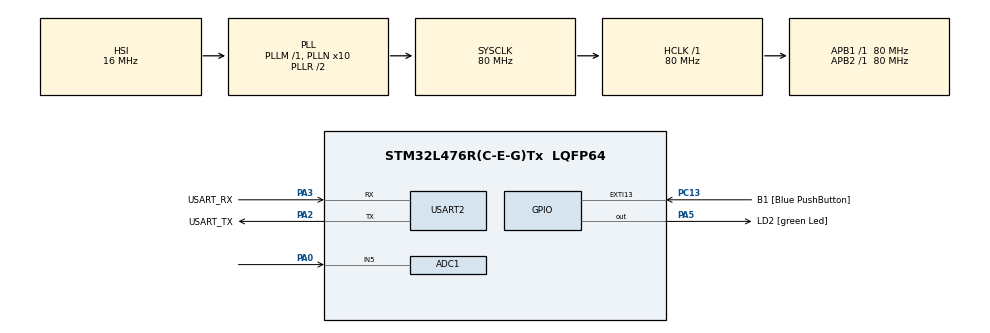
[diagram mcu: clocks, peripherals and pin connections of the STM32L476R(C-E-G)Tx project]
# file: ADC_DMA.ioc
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ADC1.Channel-1\#ChannelRegularConversion=ADC_CHANNEL_5
ADC1.ContinuousConvMode=ENABLE
ADC1.DMAContinuousRequests=ENABLE
ADC1.NbrOfConversionFlag=1
ADC1.OffsetNumber-1\#ChannelRegularConversion=ADC_OFFSET_NONE
ADC1.Rank-1\#ChannelRegularConversion=1
ADC1.SamplingTime-1\#ChannelRegularConversion=ADC_SAMPLETIME_2CYCLES_5
ADC1.master=1
Dma.ADC1.0.Direction=DMA_PERIPH_TO_MEMORY
Dma.ADC1.0.Instance=DMA1_Channel1
Dma.ADC1.0.MemDataAlignment=DMA_MDATAALIGN_HALFWORD
Dma.ADC1.0.MemInc=DMA_MINC_ENABLE
Dma.ADC1.0.Mode=DMA_CIRCULAR
Dma.ADC1.0.PeriphDataAlignment=DMA_PDATAALIGN_HALFWORD
Dma.ADC1.0.PeriphInc=DMA_PINC_DISABLE
Dma.ADC1.0.Priority=DMA_PRIORITY_LOW
Dma.Request0=ADC1
Mcu.Family=STM32L4
Mcu.Name=STM32L476R(C-E-G)Tx
Mcu.Package=LQFP64
NVIC.DMA1_Channel1_IRQn=true\:0\:0\:false\:false\:true\:false\:true\:true
NVIC.PriorityGroup=NVIC_PRIORITYGROUP_4
PA0.Signal=ADCx_IN5
PA13\ (JTMS-SWDIO).GPIO_Label=TMS
PA13\ (JTMS-SWDIO).Mode=Serial_Wire
PA13\ (JTMS-SWDIO).Signal=SYS_JTMS-SWDIO
PA14\ (JTCK-SWCLK).GPIO_Label=TCK
PA14\ (JTCK-SWCLK).Mode=Serial_Wire
PA14\ (JTCK-SWCLK).Signal=SYS_JTCK-SWCLK
PA2.GPIO_Label=USART_TX
PA2.GPIO_Mode=GPIO_MODE_AF_PP
PA2.GPIO_PuPd=GPIO_NOPULL
PA2.GPIO_Speed=GPIO_SPEED_FREQ_VERY_HIGH
PA2.Mode=Asynchronous
PA2.Signal=USART2_TX
PA3.GPIO_Label=USART_RX
PA3.GPIO_Mode=GPIO_MODE_AF_PP
PA3.GPIO_PuPd=GPIO_NOPULL
PA3.GPIO_Speed=GPIO_SPEED_FREQ_VERY_HIGH
PA3.Mode=Asynchronous
PA3.Signal=USART2_RX
PA5.GPIO_Label=LD2 [green Led]
PA5.GPIO_ModeDefaultOutputPP=GPIO_MODE_OUTPUT_PP
PA5.GPIO_PuPd=GPIO_NOPULL
PA5.GPIO_Speed=GPIO_SPEED_FREQ_LOW
PA5.Signal=GPIO_Output
PB3\ (JTDO-TRACESWO).GPIO_Label=SWO
PB3\ (JTDO-TRACESWO).Signal=SYS_JTDO-SWO
PC13.GPIO_Label=B1 [Blue PushButton]
PC13.GPIO_ModeDefaultEXTI=GPIO_MODE_IT_FALLING
PC13.GPIO_PuPd=GPIO_NOPULL
PC13.Signal=GPXTI13
PC14-OSC32_IN\ (PC14).Mode=LSE-External-Oscillator
PC14-OSC32_IN\ (PC14).Signal=RCC_OSC32_IN
PC15-OSC32_OUT\ (PC15).Mode=LSE-External-Oscillator
PC15-OSC32_OUT\ (PC15).Signal=RCC_OSC32_OUT
PH0-OSC_IN\ (PH0).Mode=HSE-External-Clock-Source
PH0-OSC_IN\ (PH0).Signal=RCC_OSC_IN
PH1-OSC_OUT\ (PH1).Signal=RCC_OSC_OUT
ProjectManager.HeapSize=0x200
ProjectManager.StackSize=0x400
ProjectManager.TargetToolchain=STM32CubeIDE
RCC.ADCFreq_Value=64000000
RCC.AHBFreq_Value=80000000
RCC.APB1Freq_Value=80000000
RCC.APB1TimFreq_Value=80000000
RCC.APB2Freq_Value=80000000
RCC.APB2TimFreq_Value=80000000
RCC.CortexFreq_Value=80000000
RCC.HCLKFreq_Value=80000000
RCC.HSE_VALUE=8000000
RCC.HSI_VALUE=16000000
RCC.MSI_VALUE=4000000
RCC.PLLN=10
RCC.PLLSourceVirtual=RCC_PLLSOURCE_HSI
RCC.SYSCLKFreq_VALUE=80000000
RCC.SYSCLKSource=RCC_SYSCLKSOURCE_PLLCLK
RCC.USBFreq_Value=64000000
RCC.VCOOutputFreq_Value=160000000
SH.ADCx_IN5.0=ADC1_IN5,IN5-Single-Ended
USART2.VirtualMode-Asynchronous=VM_ASYNC
board=NUCLEO-L476RG

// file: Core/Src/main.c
/* USER CODE BEGIN Header */
/**
  ******************************************************************************
  * @file           : main.c
  * @brief          : Main program body
  ******************************************************************************
  * @attention
  *
  * Copyright (c) 2025 STMicroelectronics.
  * All rights reserved.
  *
  * This software is licensed under terms that can be found in the LICENSE file
  * in the root directory of this software component.
  * If no LICENSE file comes with this software, it is provided AS-IS.
  *
  ******************************************************************************
  */
/* USER CODE END Header */
#include "main.h"
#include<stdio.h>
#include "string.h"

ADC_HandleTypeDef hadc1;
DMA_HandleTypeDef hdma_adc1;

UART_HandleTypeDef huart2;

void SystemClock_Config(void);
static void MX_GPIO_Init(void);
static void MX_DMA_Init(void);
static void MX_USART2_UART_Init(void);
static void MX_ADC1_Init(void);

/* USER CODE BEGIN 0 */
uint32_t adc_val = 0; // Variable to store ADC value

// Callback function called when ADC conversion is complete (DMA mode)
void HAL_ADC_ConvCpltCallback(ADC_HandleTypeDef* hadc)
{
  if (hadc->Instance == ADC1) // Check if callback is for ADC1
  {
    HAL_GPIO_TogglePin(LD2_GPIO_Port, LD2_Pin); // Toggle LED2 on each ADC update
  }
}
/* USER CODE END 0 */

int main(void)
{

  /* MCU Configuration--------------------------------------------------------*/

  HAL_Init(); // Initialize HAL library

  SystemClock_Config(); // Configure system clock

  MX_GPIO_Init();       // Initialize GPIO
  MX_DMA_Init();        // Initialize DMA
  MX_USART2_UART_Init();// Initialize UART2
  MX_ADC1_Init();       // Initialize ADC1

  /* USER CODE BEGIN 2 */
  HAL_ADC_Start_DMA(&hadc1, &adc_val, 1); // Start ADC1 in DMA mode to store result in adc_val
  /* USER CODE END 2 */

  char msg[50]; // Buffer to store UART message

  /* Infinite loop */
  /* USER CODE BEGIN WHILE */
  while (1)
  {
    // Format ADC value into string
    snprintf(msg, sizeof(msg), "ADC: %lu\r\n", adc_val);

    // Send ADC value string over UART2
    HAL_UART_Transmit(&huart2, (uint8_t*)msg, strlen(msg), HAL_MAX_DELAY);

    HAL_Delay(500); // Delay 500 ms before next transmission
  }
}

void SystemClock_Config(void)
{
  RCC_OscInitTypeDef RCC_OscInitStruct = {0};
  RCC_ClkInitTypeDef RCC_ClkInitStruct = {0};

  /** Configure the main internal regulator output voltage
  */
  if (HAL_PWREx_ControlVoltageScaling(PWR_REGULATOR_VOLTAGE_SCALE1) != HAL_OK)
  {
    Error_Handler();
  }

  /** Initializes the RCC Oscillators according to the specified parameters
  * in the RCC_OscInitTypeDef structure.
  */
  RCC_OscInitStruct.OscillatorType = RCC_OSCILLATORTYPE_HSI;
  RCC_OscInitStruct.HSIState = RCC_HSI_ON;
  RCC_OscInitStruct.HSICalibrationValue = RCC_HSICALIBRATION_DEFAULT;
  RCC_OscInitStruct.PLL.PLLState = RCC_PLL_ON;
  RCC_OscInitStruct.PLL.PLLSource = RCC_PLLSOURCE_HSI;
  RCC_OscInitStruct.PLL.PLLM = 1;
  RCC_OscInitStruct.PLL.PLLN = 10;
  RCC_OscInitStruct.PLL.PLLP = RCC_PLLP_DIV7;
  RCC_OscInitStruct.PLL.PLLQ = RCC_PLLQ_DIV2;
  RCC_OscInitStruct.PLL.PLLR = RCC_PLLR_DIV2;
  if (HAL_RCC_OscConfig(&RCC_OscInitStruct) != HAL_OK)
  {
    Error_Handler();
  }

  /** Initializes the CPU, AHB and APB buses clocks
  */
  RCC_ClkInitStruct.ClockType = RCC_CLOCKTYPE_HCLK|RCC_CLOCKTYPE_SYSCLK
                              |RCC_CLOCKTYPE_PCLK1|RCC_CLOCKTYPE_PCLK2;
  RCC_ClkInitStruct.SYSCLKSource = RCC_SYSCLKSOURCE_PLLCLK;
  RCC_ClkInitStruct.AHBCLKDivider = RCC_SYSCLK_DIV1;
  RCC_ClkInitStruct.APB1CLKDivider = RCC_HCLK_DIV1;
  RCC_ClkInitStruct.APB2CLKDivider = RCC_HCLK_DIV1;

  if (HAL_RCC_ClockConfig(&RCC_ClkInitStruct, FLASH_LATENCY_4) != HAL_OK)
  {
    Error_Handler();
  }
}

/* ADC1 Initialization Function */
static void MX_ADC1_Init(void)
{
  ADC_MultiModeTypeDef multimode = {0};
  ADC_ChannelConfTypeDef sConfig = {0};

  hadc1.Instance = ADC1;                        // Use ADC1
  hadc1.Init.ClockPrescaler = ADC_CLOCK_ASYNC_DIV1; // Set ADC clock
  hadc1.Init.Resolution = ADC_RESOLUTION_12B;       // 12-bit resolution
  hadc1.Init.DataAlign = ADC_DATAALIGN_RIGHT;       // Right-aligned data
  hadc1.Init.ScanConvMode = ADC_SCAN_DISABLE;       // Single channel scan
  hadc1.Init.EOCSelection = ADC_EOC_SINGLE_CONV;    // End of conversion after each conversion
  hadc1.Init.LowPowerAutoWait = DISABLE;           // No auto wait
  hadc1.Init.ContinuousConvMode = DISABLE;         // Single conversion mode (DMA handles continuous)
  hadc1.Init.NbrOfConversion = 1;                  // Only one channel
  hadc1.Init.DiscontinuousConvMode = DISABLE;      // No discontinuous mode
  hadc1.Init.ExternalTrigConv = ADC_SOFTWARE_START; // Software trigger
  hadc1.Init.ExternalTrigConvEdge = ADC_EXTERNALTRIGCONVEDGE_NONE;
  hadc1.Init.DMAContinuousRequests = ENABLE;      // Enable continuous DMA requests
  hadc1.Init.Overrun = ADC_OVR_DATA_PRESERVED;    // Preserve old data on overrun
  hadc1.Init.OversamplingMode = DISABLE;          // No oversampling

  if (HAL_ADC_Init(&hadc1) != HAL_OK)
  {
    Error_Handler(); // Handle ADC init error
  }

  multimode.Mode = ADC_MODE_INDEPENDENT;          // Independent ADC mode
  if (HAL_ADCEx_MultiModeConfigChannel(&hadc1, &multimode) != HAL_OK)
  {
    Error_Handler(); // Handle multimode config error
  }

  sConfig.Channel = ADC_CHANNEL_5;               // ADC channel 5
  sConfig.Rank = ADC_REGULAR_RANK_1;             // First in regular sequence
  sConfig.SamplingTime = ADC_SAMPLETIME_2CYCLES_5; // Sampling time
  sConfig.SingleDiff = ADC_SINGLE_ENDED;         // Single-ended input
  sConfig.OffsetNumber = ADC_OFFSET_NONE;        // No offset
  sConfig.Offset = 0;

  if (HAL_ADC_ConfigChannel(&hadc1, &sConfig) != HAL_OK)
  {
    Error_Handler(); // Handle channel config error
  }
}

/* USART2 Initialization Function */
static void MX_USART2_UART_Init(void)
{
  huart2.Instance = USART2;              // UART2 instance
  huart2.Init.BaudRate = 115200;         // Baud rate 115200
  huart2.Init.WordLength = UART_WORDLENGTH_8B; // 8-bit word
  huart2.Init.StopBits = UART_STOPBITS_1;      // 1 stop bit
  huart2.Init.Parity = UART_PARITY_NONE;       // No parity
  huart2.Init.Mode = UART_MODE_TX_RX;          // TX and RX enabled
  huart2.Init.HwFlowCtl = UART_HWCONTROL_NONE; // No hardware flow control
  huart2.Init.OverSampling = UART_OVERSAMPLING_16; // Oversampling 16
  huart2.Init.OneBitSampling = UART_ONE_BIT_SAMPLE_DISABLE;
  huart2.AdvancedInit.AdvFeatureInit = UART_ADVFEATURE_NO_INIT;

  if (HAL_UART_Init(&huart2) != HAL_OK)
  {
    Error_Handler(); // Handle UART init error
  }
}

static void MX_DMA_Init(void)
{

  /* DMA controller clock enable */
  __HAL_RCC_DMA1_CLK_ENABLE();

  /* DMA interrupt init */
  /* DMA1_Channel1_IRQn interrupt configuration */
  HAL_NVIC_SetPriority(DMA1_Channel1_IRQn, 0, 0);
  HAL_NVIC_EnableIRQ(DMA1_Channel1_IRQn);

}

static void MX_GPIO_Init(void)
{
  GPIO_InitTypeDef GPIO_InitStruct = {0};

  /* GPIO Ports Clock Enable */
  __HAL_RCC_GPIOC_CLK_ENABLE();
  __HAL_RCC_GPIOH_CLK_ENABLE();
  __HAL_RCC_GPIOA_CLK_ENABLE();
  __HAL_RCC_GPIOB_CLK_ENABLE();

  /*Configure GPIO pin Output Level */
  HAL_GPIO_WritePin(LD2_GPIO_Port, LD2_Pin, GPIO_PIN_RESET);

  /*Configure GPIO pin : B1_Pin */
  GPIO_InitStruct.Pin = B1_Pin;
  GPIO_InitStruct.Mode = GPIO_MODE_IT_FALLING;
  GPIO_InitStruct.Pull = GPIO_NOPULL;
  HAL_GPIO_Init(B1_GPIO_Port, &GPIO_InitStruct);

  /*Configure GPIO pin : LD2_Pin */
  GPIO_InitStruct.Pin = LD2_Pin;
  GPIO_InitStruct.Mode = GPIO_MODE_OUTPUT_PP;
  GPIO_InitStruct.Pull = GPIO_NOPULL;
  GPIO_InitStruct.Speed = GPIO_SPEED_FREQ_LOW;
  HAL_GPIO_Init(LD2_GPIO_Port, &GPIO_InitStruct);

}

void Error_Handler(void)
{
  __disable_irq();
  while (1)
  {
  }
}
